# MM32SPIN0230 register map
Series: ARM Cortex M0; File version: 1.0
CPU: CM0 r0p0, little endian, no MPU, no FPU, 2 interrupt priority bits
Registers are 32-bit, read-write, reset 0x0 unless marked. A register's access mark holds for its fields unless they carry their own. Offsets are from the block's base; [hi:lo] are bit positions; {n}, {i} and the like mark numbered series.

## TIM13
Base 0x40001800
Same registers: TIM14 0x40014000
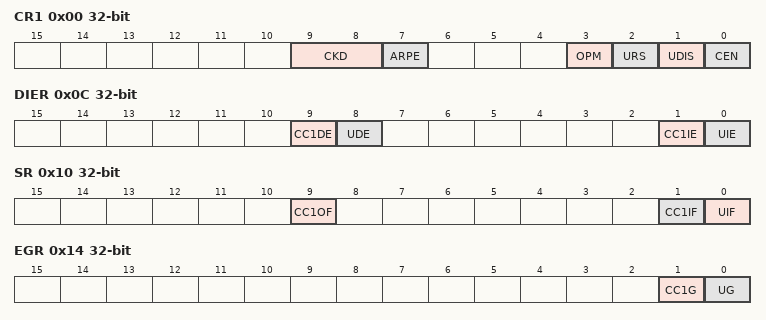
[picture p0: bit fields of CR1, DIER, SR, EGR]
0x00 CR1 — Control Register 1
  [9:8] CKD, [7] ARPE, [3] OPM, [2] URS, [1] UDIS, [0] CEN
0x0C DIER — DMA/Interrupt Enable Register (DMA is only suitable for the chip with built in DMA)
  [9] CC1DE, [8] UDE, [1] CC1IE, [0] UIE
0x10 SR — Status Register
  [9] CC1OF write-0-clears, [1] CC1IF write-0-clears, [0] UIF write-0-clears
0x14 EGR wo — Event Generation Register
  [1] CC1G, [0] UG
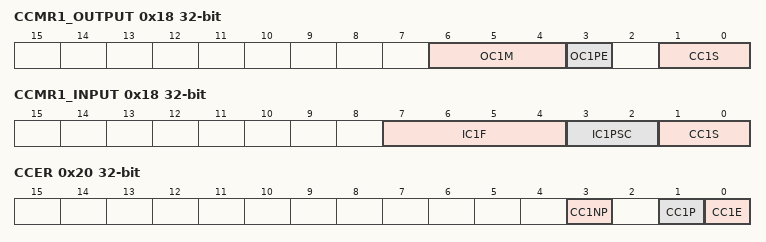
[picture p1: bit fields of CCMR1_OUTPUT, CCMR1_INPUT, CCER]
0x18 CCMR1_OUTPUT — Capture/Compare Mode Register 1
  [6:4] OC1M, [3] OC1PE, [1:0] CC1S
0x18 CCMR1_INPUT (alternate view of CCMR1_OUTPUT) — Capture/Compare Mode Register 1
  [7:4] IC1F, [3:2] IC1PSC, [1:0] CC1S
0x20 CCER — Capture/Compare Enable Register
  [3] CC1NP, [1] CC1P, [0] CC1E
0x24 CNT — Counter
  [15:0] CNT
0x28 PSC — Prescaler
  [15:0] PSC
0x2C ARR — Auto Reload Register
  [15:0] ARR
0x34 CCR1 — Capture/Compare Register 1
  [15:0] CCR1
0x44 BDTR — Break And Dead-Time Register
  [15] MOE

## TIM2
Base 0x40000000
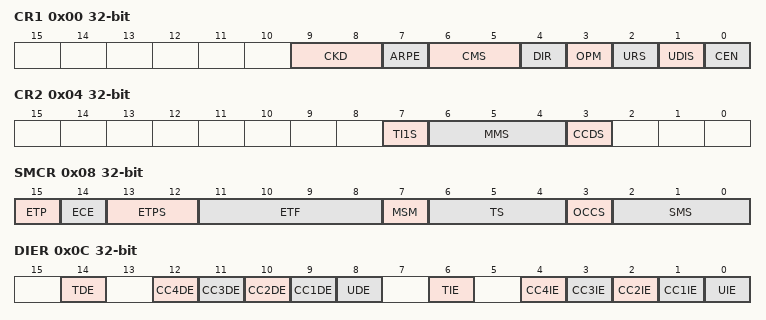
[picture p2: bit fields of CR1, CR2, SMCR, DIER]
0x00 CR1 — Control Register 1
  [9:8] CKD, [7] ARPE, [6:5] CMS, [4] DIR, [3] OPM, [2] URS, [1] UDIS, [0] CEN
0x04 CR2 — Control Register 2
  [7] TI1S, [6:4] MMS, [3] CCDS
0x08 SMCR — Slave Mode Control Register
  [15] ETP, [14] ECE, [13:12] ETPS, [11:8] ETF, [7] MSM, [6:4] TS, [3] OCCS, [2:0] SMS
0x0C DIER — DMA/Interrupt Enable Register (DMA is only suitable for the chip with built in DMA)
  [14] TDE, [n+8] CC{n}DE (n=1..4), [8] UDE, [6] TIE, [n] CC{n}IE (n=1..4), [0] UIE
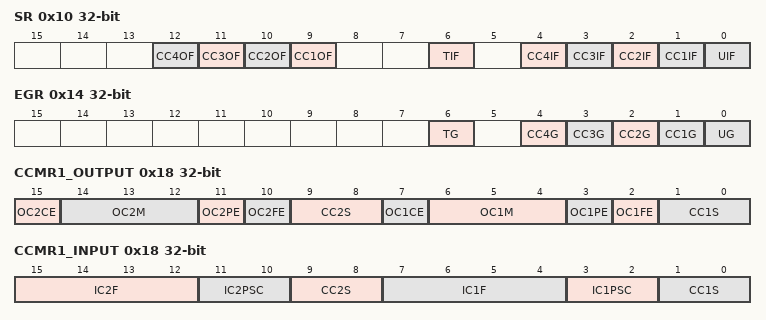
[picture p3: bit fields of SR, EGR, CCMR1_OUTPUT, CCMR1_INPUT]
0x10 SR — Status Register
  [n+8] CC{n}OF write-0-clears (n=1..4), [6] TIF write-0-clears, [n] CC{n}IF write-0-clears (n=1..4), [0] UIF write-0-clears
0x14 EGR wo — Event Generation Register
  [6] TG, [n] CC{n}G (n=1..4), [0] UG
0x18 CCMR1_OUTPUT — Capture/Compare Mode Register 1
  [15] OC2CE, [14:12] OC2M, [11] OC2PE, [10] OC2FE, [9:8] CC2S, [7] OC1CE, [6:4] OC1M, [3] OC1PE, [2] OC1FE, [1:0] CC1S
0x18 CCMR1_INPUT (alternate view of CCMR1_OUTPUT) — Capture/Compare Mode Register 1
  [15:12] IC2F, [11:10] IC2PSC, [9:8] CC2S, [7:4] IC1F, [3:2] IC1PSC, [1:0] CC1S
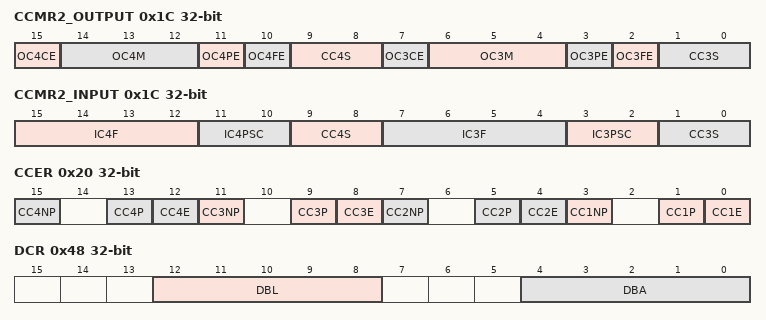
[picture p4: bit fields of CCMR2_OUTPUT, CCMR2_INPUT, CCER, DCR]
0x1C CCMR2_OUTPUT — Capture/Compare Mode Register 2
  [15] OC4CE, [14:12] OC4M, [11] OC4PE, [10] OC4FE, [9:8] CC4S, [7] OC3CE, [6:4] OC3M, [3] OC3PE, [2] OC3FE, [1:0] CC3S
0x1C CCMR2_INPUT (alternate view of CCMR2_OUTPUT) — Capture/Compare Mode Register 2
  [15:12] IC4F, [11:10] IC4PSC, [9:8] CC4S, [7:4] IC3F, [3:2] IC3PSC, [1:0] CC3S
0x20 CCER — Capture/Compare Enable Register
  [4n-1] CC{n}NP (n=1..4), [4n-3] CC{n}P (n=1..4), [4n-4] CC{n}E (n=1..4)
0x24 CNT — Counter
0x28 PSC — Prescaler
  [15:0] PSC
0x2C ARR — Auto Reload Register
{0x30+4i} CCR{i} (i=1..4) — Capture/Compare Register {i}
0x48 DCR — DMA Control Register (only suitable for the chip with built in DMA)
  [12:8] DBL, [4:0] DBA
0x4C DMAR wo — DMA Address Register Of Continuous Mode (only suitable for the chip with built in DMA)
  [15:0] DMAB
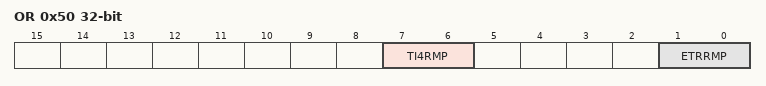
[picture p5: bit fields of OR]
0x50 OR — Input Option Register
  [7:6] TI4RMP, [1:0] ETRRMP

## TIM6
Base 0x40001000
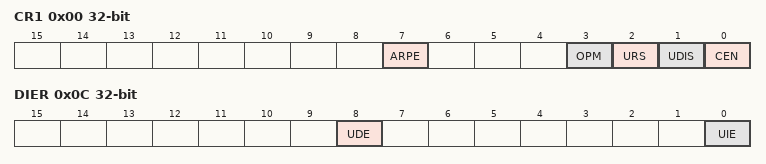
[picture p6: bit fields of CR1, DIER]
0x00 CR1 — Control Register 1
  [7] ARPE, [3] OPM, [2] URS, [1] UDIS, [0] CEN
0x0C DIER — DMA/Interrupt Enable Register (DMA is only suitable for the chip with built in DMA)
  [8] UDE, [0] UIE
0x10 SR — Status Register
  [0] UIF write-0-clears
0x14 EGR wo — Event Generation Register
  [0] UG
0x24 CNT — Counter
  [15:0] CNT
0x28 PSC — Prescaler
  [15:0] PSC
0x2C ARR — Auto Reload Register
  [15:0] ARR

## USART1
Base 0x40010C00
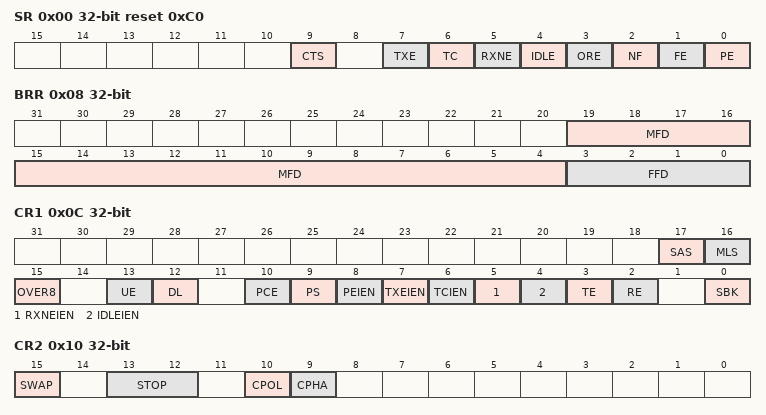
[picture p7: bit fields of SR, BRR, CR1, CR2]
0x00 SR reset 0xC0 — Status register
  [9] CTS write-0-clears, [7] TXE ro, [6] TC ro, [5] RXNE write-0-clears, [4] IDLE ro, [3] ORE ro, [2] NF ro, [1] FE ro, [0] PE ro
0x04 DR reset 0x1FF — Data register
  [8:0] DR
0x08 BRR — Baud rate register
  [19:4] MFD, [3:0] FFD
0x0C CR1 — Control register 1
  [17] SAS, [16] MLS, [15] OVER8, [13] UE, [12] DL, [10] PCE, [9] PS, [8] PEIEN, [7] TXEIEN, [6] TCIEN, [5] RXNEIEN, [4] IDLEIEN, [3] TE, [2] RE, [0] SBK
0x10 CR2 — Control register 2
  [15] SWAP, [13:12] STOP, [10] CPOL, [9] CPHA
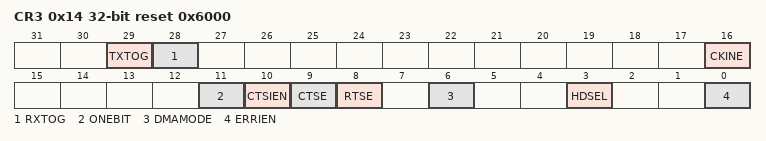
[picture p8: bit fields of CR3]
0x14 CR3 reset 0x6000 — Control register 3
  [29] TXTOG, [28] RXTOG, [16] CKINE, [11] ONEBIT, [10] CTSIEN, [9] CTSE, [8] RTSE, [6] DMAMODE, [3] HDSEL, [0] ERRIEN
